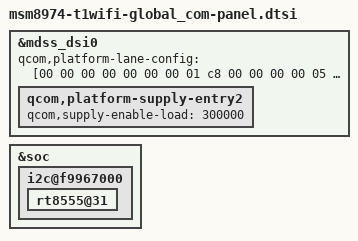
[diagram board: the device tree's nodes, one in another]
/* Copyright (c) 2012, Code Aurora Forum. All rights reserved.
 *
 * This program is free software; you can redistribute it and/or modify
 * it under the terms of the GNU General Public License version 2 and
 * only version 2 as published by the Free Software Foundation.
 *
 * This program is distributed in the hope that it will be useful,
 * but WITHOUT ANY WARRANTY; without even the implied warranty of
 * MERCHANTABILITY or FITNESS FOR A PARTICULAR PURPOSE.  See the
 * GNU General Public License for more details.
 */

&mdss_dsi0 {
	qcom,platform-lane-config = [00 00 00 00 00 00 00 01 c8
			00 00 00 00 05 00 00 01 c8
			00 00 00 00 0a 00 00 01 c8
			00 00 00 00 0f 00 00 01 c8
			00 c0 00 00 00 00 00 01 bb];
	qcom,platform-supply-entry2 {
		qcom,supply-enable-load = <300000>;
	};
};

&soc {
	i2c@f9967000 {
		rt8555@31 {
			status = "ok";
		};
	};
};
